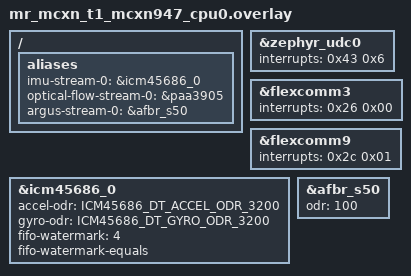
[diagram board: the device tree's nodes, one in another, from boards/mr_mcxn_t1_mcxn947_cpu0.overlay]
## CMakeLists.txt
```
#-------------------------------------------------------------------------------
# Zephyr Spinali Application
#
# Copyright (c) 2023 CogniPilot Foundation
# SPDX-License-Identifier: Apache-2.0

cmake_minimum_required(VERSION 3.13.1)

# Pull the MR-MCXN-T1 daughter-board nodes from the upstream shield.
set(SHIELD mr_mcxn_t1_optical_flow)

find_package(Zephyr REQUIRED HINTS $ENV{ZEPHYR_BASE})

project(optical_flow LANGUAGES C)

set(flags
  -std=c11
  -Wall
  -Wextra
  -Werror
  -Wstrict-prototypes
  -Waggregate-return
  -Wbad-function-cast
  -Wcast-align
  -Wcast-qual
  -Wfloat-equal
  -Wformat-security
  -Wlogical-op
  -Wmissing-declarations
  -Wmissing-include-dirs
  -Wmissing-prototypes
  -Wnested-externs
  -Wpointer-arith
  -Wredundant-decls
  -Wsequence-point
  -Wshadow
  -Wstrict-prototypes
  -Wswitch
  -Wundef
  -Wunreachable-code
  -Wunused-but-set-parameter
  -Wwrite-strings
  )
string(JOIN " " flags ${flags})

set(SOURCE_FILES
  src/boot_banner.c
  )

set_source_files_properties(
  ${SOURCE_FILES}
  PROPERTIES COMPILE_FLAGS
  "${flags}"
  )

target_sources(app PRIVATE ${SOURCE_FILES})

target_include_directories(app SYSTEM BEFORE PRIVATE ${ZEPHYR_BASE}/include ${CMAKE_BINARY_DIR})

# vi: ts=2 sw=2 et
```

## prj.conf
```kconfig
CONFIG_SPINALI=y
CONFIG_SPINALI_APP_NAME="MCXN-T1-Optical-Flow"

# CONFIG_BOOTLOADER_MCUBOOT=y
# CONFIG_MCUBOOT_SIGNATURE_KEY_FILE="../../../bootloader/mcuboot/root-rsa-2048.pem"
CONFIG_ZCBOR=y
CONFIG_MCUMGR=y
CONFIG_MCUMGR_TRANSPORT_UDP=y
CONFIG_MCUMGR_TRANSPORT_UDP_IPV4=y
CONFIG_MCUMGR_GRP_OS=y
CONFIG_MCUMGR_GRP_OS_INFO=y
CONFIG_MCUMGR_GRP_OS_INFO_BUILD_DATE_TIME=y
CONFIG_MCUMGR_GRP_OS_INFO_CUSTOM_HOOKS=y
CONFIG_MCUMGR_MGMT_NOTIFICATION_HOOKS=y
CONFIG_HWINFO=y
CONFIG_MCUMGR_GRP_OS_BOOTLOADER_INFO=y
CONFIG_MCUMGR_GRP_OS_MCUMGR_PARAMS=y
CONFIG_THREAD_MONITOR=y
CONFIG_THREAD_NAME=y
CONFIG_MCUMGR_GRP_OS_TASKSTAT=y
CONFIG_MCUMGR_GRP_OS_TASKSTAT_USE_THREAD_NAME_FOR_NAME=y
CONFIG_THREAD_STACK_INFO=y
CONFIG_FLASH=y
CONFIG_FLASH_MAP=y
CONFIG_IMG_MANAGER=y
CONFIG_STREAM_FLASH=y
CONFIG_MCUMGR_GRP_IMG=y
CONFIG_MCUMGR_GRP_IMG_SLOT_INFO=y
CONFIG_SHELL_BACKEND_DUMMY=y
CONFIG_BASE64=y
CONFIG_MCUMGR_GRP_SHELL=y
CONFIG_STATS=y
CONFIG_STATS_NAMES=y
CONFIG_MCUMGR_GRP_STAT=y
CONFIG_SYS_CLOCK_TICKS_PER_SEC=10000
CONFIG_TICKLESS_KERNEL=n
CONFIG_I3C=n
CONFIG_TEST_RANDOM_GENERATOR=y
CONFIG_FPU=y

CONFIG_NET_PKT_RX_COUNT=24
CONFIG_NET_BUF_RX_COUNT=45
CONFIG_NET_BUF_TX_COUNT=60
CONFIG_NET_PKT_TX_COUNT=60

CONFIG_ZROS_SENSE_STREAM=y
CONFIG_ZROS_SENSE_STREAM_IMU=y
CONFIG_ZROS_SENSE_STREAM_MAG=n
CONFIG_ZROS_SENSE_STREAM_OPTICAL_FLOW=y
CONFIG_ZROS_SENSE_STREAM_ARGUS_POINTCLOUD=y
CONFIG_ZROS_SENSE_STREAM_ARGUS=y

CONFIG_SHELL=y
CONFIG_SENSOR=y
CONFIG_SENSOR_SHELL=y
CONFIG_SENSOR_INFO=y


CONFIG_SYNAPSE_PB=y
CONFIG_NANOPB=y

CONFIG_SPINALI_SYNAPSE_TOPIC=y
CONFIG_SPINALI_CORE_COMMON=y
CONFIG_SPINALI_CORE_COMMON_BOOT_BANNER=y
CONFIG_ZROS=y
CONFIG_SHELL_STACK_SIZE=8192
CONFIG_INIT_STACKS=y

CONFIG_LOG=y
CONFIG_LOG_CMDS=y
CONFIG_LOG_MODE_DEFERRED=y

CONFIG_SPINALI_OPTICAL_FLOW_LOG_LEVEL_DBG=y
# CONFIG_NET_LOG=y
# CONFIG_NET_TCP_LOG_LEVEL_DBG=y
# CONFIG_COMPILER_OPT="-DZENOH_DEBUG=2"

CONFIG_SENSOR_SHELL_THREAD_STACK_SIZE=8192
CONFIG_SENSOR_LOG_LEVEL_DBG=n

# modules

# General config
CONFIG_MAIN_THREAD_PRIORITY=5
CONFIG_SYSTEM_WORKQUEUE_PRIORITY=-2

CONFIG_NET_SHELL=y
CONFIG_NETWORKING=y
CONFIG_NET_IPV4=y
CONFIG_NET_IPV6=n
CONFIG_NET_UDP=y
CONFIG_NET_TCP=y
CONFIG_NET_SOCKETS=y

# Network address config
CONFIG_NET_HOSTNAME="optical-flow"
CONFIG_NET_CONFIG_SETTINGS=y
CONFIG_NET_STATISTICS=y
CONFIG_NET_MGMT_EVENT_INFO=y
CONFIG_NET_MGMT_EVENT_MONITOR=y
CONFIG_NET_BUF_POOL_USAGE=y
CONFIG_NET_DEBUG_NET_PKT_ALLOC=y
CONFIG_NET_CONFIG_NEED_IPV4=y
CONFIG_NET_CONFIG_MY_IPV4_ADDR="10.58.0.12"
CONFIG_NET_CONFIG_MY_IPV4_NETMASK="255.255.0.0"

# STATS
CONFIG_THREAD_RUNTIME_STATS=y
CONFIG_SCHED_THREAD_USAGE=y
CONFIG_SCHED_THREAD_USAGE_ANALYSIS=y
CONFIG_SCHED_THREAD_USAGE_ALL=y
CONFIG_SCHED_THREAD_USAGE_AUTO_ENABLE=y

CONFIG_SPEED_OPTIMIZATIONS=y
CONFIG_ZVFS_OPEN_MAX=16
CONFIG_HEAP_MEM_POOL_SIZE=49152

CONFIG_PX4_MSGS=y
CONFIG_SYNAPSE_ZENOH_PX4=y
CONFIG_SYNAPSE_ZENOH_PX4_LOG_LEVEL_DBG=y
CONFIG_SYNAPSE_ZENOH_PX4_RIHS_HASH=y
CONFIG_SYNAPSE_ZENOH_PX4_RUNTIME_CONFIG=y
CONFIG_SYNAPSE_ZENOH_PX4_PERSIST=y
CONFIG_SYNAPSE_ZENOH_PX4_RMW_COMPAT=y
CONFIG_SYNAPSE_ZENOH_PX4_MODE_CLIENT=y
CONFIG_SYNAPSE_ZENOH_PX4_LOCATOR="tcp/10.58.0.1:7447"

CONFIG_SYNAPSE_ZENOH_PX4_SENSOR_COMBINED_RATE_HZ=100
CONFIG_SYNAPSE_ZENOH_PX4_OPTICAL_FLOW_RATE_HZ=50
CONFIG_SYNAPSE_ZENOH_PX4_DISTANCE_SENSOR_RATE_HZ=50

CONFIG_SYNAPSE_ZENOH_PX4_MAG_RATE_HZ=0
CONFIG_SYNAPSE_ZENOH_PX4_GNSS_RATE_HZ=0


CONFIG_ZENOH_PICO=y
CONFIG_ZENOH_PICO_MULTI_THREAD=y

CONFIG_ZENOH_PICO_LINK_TCP=y
CONFIG_ZENOH_PICO_LINK_UDP_UNICAST=y
CONFIG_ZENOH_PICO_ZEPHYR_TASK_STACK_SIZE=6144

CONFIG_RTIO_WORKQ_THREADS_POOL_STACK_SIZE=4096
```

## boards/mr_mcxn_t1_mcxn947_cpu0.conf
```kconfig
CONFIG_ICM45686_STREAM=y
CONFIG_PAA3905_STREAM=y
CONFIG_BMM350_STREAM=n
CONFIG_RTIO_WORKQ_THREADS_POOL_PRIO=4
CONFIG_I2C_RTIO_SQ_SIZE=8
CONFIG_I2C_RTIO_CQ_SIZE=8
```

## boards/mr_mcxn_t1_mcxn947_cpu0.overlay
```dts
/* SPDX-License-Identifier: Apache-2.0 */
/* Copyright 2025 CogniPilot Foundation */

/*
 * The AFBR-S50, PAA3905 and their FlexComm3/9 pinctrl are provided by the
 * upstream `mr_mcxn_t1_optical_flow` shield (selected in CMakeLists.txt).
 * Only application-specific aliases and overrides remain here.
 */
#include <zephyr/dt-bindings/sensor/afbr_s50.h>
#include <zephyr/dt-bindings/sensor/icm45686.h>

/ {
	aliases {
		imu-stream-0 = &icm45686_0;
		optical-flow-stream-0 = &paa3905;
		argus-stream-0 = &afbr_s50;
	};
};

/* USB shell IRQ priority lower than SPI IRQs */
&zephyr_udc0 {
	interrupts = <0x43 0x6>;
};

/* AFBR-S50 SPI priority lower than the IMU running at 800-Hz */
&flexcomm3 {
	interrupts = <0x26 0x00>;
};

/* PAA3905 SPI priority lower than the IMU running at 800-Hz */
&flexcomm9 {
	interrupts = <0x2c 0x01>;
};

&icm45686_0 {
	/* Configure to output 4-samples every 1.25-ms (800-Hz) */
	accel-odr = <ICM45686_DT_ACCEL_ODR_3200>;
	gyro-odr = <ICM45686_DT_GYRO_ODR_3200>;
	fifo-watermark = <4>;
	fifo-watermark-equals;
};

/* Application runs the ToF at 100-Hz (shield default is 50). */
&afbr_s50 {
	odr = <100>;
};
```

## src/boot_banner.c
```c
/*
 * Copyright (c) 2023 CogniPilot Foundation
 * SPDX-License-Identifier: Apache-2.0
 */

#include <zephyr/kernel.h>
#include <zephyr/logging/log.h>

#if defined(CONFIG_SPINALI_CORE_COMMON_BOOT_BANNER)
#include <stdio.h>
#endif

#include <spinali/core/common.h>

LOG_MODULE_REGISTER(optical_flow_boot_banner, CONFIG_SPINALI_OPTICAL_FLOW_LOG_LEVEL);

static int optical_flow_boot_banner_sys_init(void)
{
	LOG_INF("MCXN-T1-ROS2-Node Optical Flow %d.%d.%d", CONFIG_SPINALI_VERSION_MAJOR,
		CONFIG_SPINALI_VERSION_MINOR, CONFIG_SPINALI_VERSION_PATCH);
#if defined(CONFIG_SPINALI_CORE_COMMON_BOOT_BANNER)
	printf("%s", banner_spinali);
#endif
	return 0;
};

SYS_INIT(optical_flow_boot_banner_sys_init, APPLICATION, 0);

// vi: ts=4 sw=4 et
```
